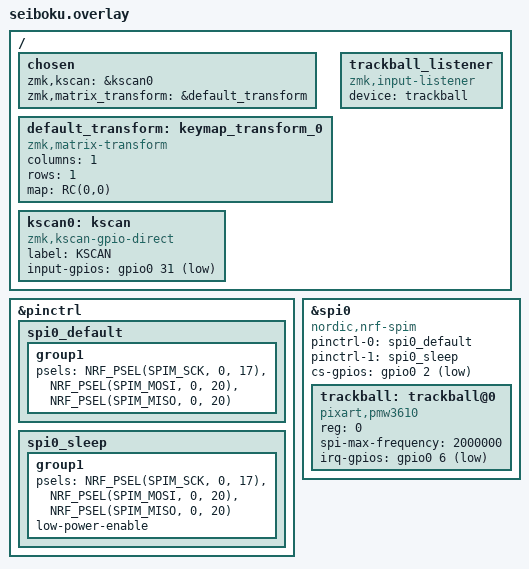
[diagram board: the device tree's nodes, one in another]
#include <dt-bindings/zmk/matrix_transform.h>

// ブレイクアウトボードは、上からSDIO、SCLK、NSC、NRESET、MOT
// それぞれ、P0.20、P0.17、P0.02、なし、P0.06に接続

/ {
    chosen {
        zmk,kscan = &kscan0;
        zmk,matrix_transform = &default_transform;
    };

    default_transform: keymap_transform_0 {
        compatible = "zmk,matrix-transform";
        columns = <1>;
        rows = <1>;
        map = <RC(0,0)>;
    };

    kscan0: kscan {
        compatible = "zmk,kscan-gpio-direct";
        label = "KSCAN";
        input-gpios = <&gpio0 31 (GPIO_ACTIVE_LOW | GPIO_PULL_UP)>;
    };
};

&pinctrl {
    spi0_default: spi0_default {
        group1 {
			psels = <NRF_PSEL(SPIM_SCK, 0, 17)>, //SCLK = P0.17
			    	<NRF_PSEL(SPIM_MOSI, 0, 20)>, //SDIO = P0.20
			    	<NRF_PSEL(SPIM_MISO, 0, 20)>; //SDIO = P0.20
        };
    };

    spi0_sleep: spi0_sleep {
        group1 {
			psels = <NRF_PSEL(SPIM_SCK, 0, 17)>, //SCLK = P0.17
			    	<NRF_PSEL(SPIM_MOSI, 0, 20)>, //SDIO = P0.20
			    	<NRF_PSEL(SPIM_MISO, 0, 20)>; //SDIO = P0.20
            low-power-enable;
        };
    };
};

&spi0 {
    status = "okay";
    compatible = "nordic,nrf-spim";
    pinctrl-0 = <&spi0_default>;
    pinctrl-1 = <&spi0_sleep>;
    pinctrl-names = "default", "sleep";
    // cs-gpios = <&xiao_d 7 GPIO_ACTIVE_LOW>; //NCS
    cs-gpios = <&gpio0 2 GPIO_ACTIVE_LOW>; //NCS = P0.02


    trackball: trackball@0 {
        status = "okay";
        compatible = "pixart,pmw3610";
        reg = <0>;
        spi-max-frequency = <2000000>;
        // irq-gpios = <&xiao_d 10 (GPIO_ACTIVE_LOW | GPIO_PULL_UP)>; //MOT
        irq-gpios = <&gpio0 6 (GPIO_ACTIVE_LOW | GPIO_PULL_UP)>; //MOT = P0.06

    };
};

/ {
  trackball_listener {
    compatible = "zmk,input-listener";
    device = <&trackball>;

  };
};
